VERSION ""

NS_ :

BS_:

BU_:

BO_ 550 INV1command: 8 Vector__XXX
 SG_ throttleCurrent1 : 0|16@1- (1,0) [0|0] "%throttle" Vector__XXX

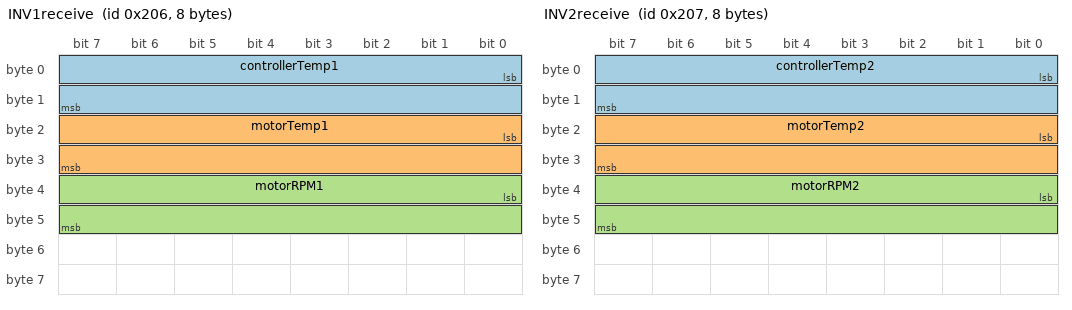
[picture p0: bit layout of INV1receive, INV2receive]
BO_ 518 INV1receive: 8 Vector__XXX
 SG_ controllerTemp1 : 0|16@1- (1,0) [0|0] "10*C" Vector__XXX
 SG_ motorTemp1 : 16|16@1+ (1,0) [0|0] "10*C" Vector__XXX
 SG_ motorRPM1 : 32|16@1+ (1,0) [0|0] "RPM" Vector__XXX

BO_ 551 INV2command: 8 Vector__XXX
 SG_ throttleCurrent2 : 0|16@1- (1,0) [0|0] "%throttle" Vector__XXX

BO_ 519 INV2receive: 8 Vector__XXX
 SG_ controllerTemp2 : 0|16@1+ (1,0) [0|0] "10*C" Vector__XXX
 SG_ motorTemp2 : 16|16@1+ (1,0) [0|0] "10*C" Vector__XXX
 SG_ motorRPM2 : 32|16@1+ (1,0) [0|0] "RPM" Vector__XXX
